# STM32F407 register map
File version: 1.2
CPU: CM4 r1p0, little endian, no MPU, no FPU, 4 interrupt priority bits
Registers are 32-bit, read-write, reset 0x0 unless marked. A register's access mark holds for its fields unless they carry their own. Offsets are from the block's base; [hi:lo] are bit positions.

## USART1 — Universal synchronous asynchronous receiver transmitter
Base 0x40011000
Same registers: USART2 0x40004400, USART3 0x40004800, USART6 0x40011400
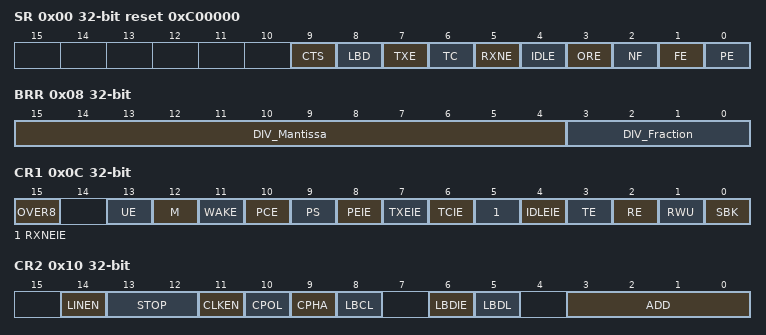
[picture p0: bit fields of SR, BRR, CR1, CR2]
0x00 SR access per field reset 0xC00000 — Status register
  [9] CTS rw — CTS flag
  [8] LBD rw — LIN break detection flag
  [7] TXE ro — Transmit data register empty
  [6] TC rw — Transmission complete
  [5] RXNE rw — Read data register not empty
  [4] IDLE ro — IDLE line detected
  [3] ORE ro — Overrun error
  [2] NF ro — Noise detected flag
  [1] FE ro — Framing error
  [0] PE ro — Parity error
0x04 DR — Data register
  [8:0] DR — Data value
0x08 BRR — Baud rate register
  [15:4] DIV_Mantissa — mantissa of USARTDIV
  [3:0] DIV_Fraction — fraction of USARTDIV
0x0C CR1 — Control register 1
  [15] OVER8 — Oversampling mode
    0=Oversample16 (Oversampling by 16); 1=Oversample8 (Oversampling by 8)
  [13] UE — USART enable
    0=Disabled (USART prescaler and outputs disabled); 1=Enabled (USART enabled)
  [12] M — Word length
    0=8 data bits; 1=9 data bits
  [11] WAKE — Wakeup method
    0=IdleLine (USART wakeup on idle line); 1=AddressMark (USART wakeup on address mark)
  [10] PCE — Parity control enable
    0=Disabled (Parity control disabled); 1=Enabled (Parity control enabled)
  [9] PS — Parity selection
    0=Even parity; 1=Odd (Odd parity)
  [8] PEIE — PE interrupt enable
    0=Disabled (PE interrupt disabled); 1=Enabled (PE interrupt enabled)
  [7] TXEIE — TXE interrupt enable
    0=Disabled (TXE interrupt disabled); 1=Enabled (TXE interrupt enabled)
  [6] TCIE — Transmission complete interrupt enable
    0=Disabled (TC interrupt disabled); 1=Enabled (TC interrupt enabled)
  [5] RXNEIE — RXNE interrupt enable
    0=Disabled (RXNE interrupt disabled); 1=Enabled (RXNE interrupt enabled)
  [4] IDLEIE — IDLE interrupt enable
    0=Disabled (IDLE interrupt disabled); 1=Enabled (IDLE interrupt enabled)
  [3] TE — Transmitter enable
    0=Disabled (Transmitter disabled); 1=Enabled (Transmitter enabled)
  [2] RE — Receiver enable
    0=Disabled (Receiver disabled); 1=Enabled (Receiver enabled)
  [1] RWU — Receiver wakeup
    0=Active (Receiver in active mode); 1=Mute (Receiver in mute mode)
  [0] SBK — Send break
    0=No break character is transmitted; 1=Break character transmitted
0x10 CR2 — Control register 2
  [14] LINEN — LIN mode enable
    0=Disabled (LIN mode disabled); 1=Enabled (LIN mode enabled)
  [13:12] STOP — STOP bits
    0=1 stop bit; 1=Stop0p5 (0.5 stop bits); 2=2 stop bits; 3=Stop1p5 (1.5 stop bits)
  [11] CLKEN — Clock enable
    0=Disabled (CK pin disabled); 1=Enabled (CK pin enabled)
  [10] CPOL — Clock polarity
    0=Low (Steady low value on CK pin outside transmission window); 1=High (Steady high value on CK pin outside transmission window)
  [9] CPHA — Clock phase
    0=First (The first clock transition is the first data capture edge); 1=Second (The second clock transition is the first data capture edge)
  [8] LBCL — Last bit clock pulse
  [6] LBDIE — LIN break detection interrupt enable
    0=Disabled (LIN break detection interrupt disabled); 1=Enabled (LIN break detection interrupt enabled)
  [5] LBDL — lin break detection length
    0=10-bit break detection; 1=11-bit break detection
  [3:0] ADD — Address of the USART node
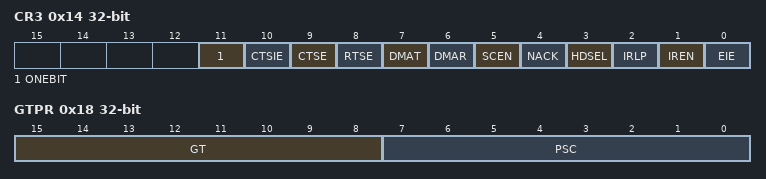
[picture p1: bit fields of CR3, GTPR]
0x14 CR3 — Control register 3
  [11] ONEBIT — One sample bit method enable
    0=Sample3 (Three sample bit method); 1=Sample1 (One sample bit method)
  [10] CTSIE — CTS interrupt enable
    0=Disabled (CTS interrupt disabled); 1=Enabled (CTS interrupt enabled)
  [9] CTSE — CTS enable
    0=Disabled (CTS hardware flow control disabled); 1=Enabled (CTS hardware flow control enabled)
  [8] RTSE — RTS enable
    0=Disabled (RTS hardware flow control disabled); 1=Enabled (RTS hardware flow control enabled)
  [7] DMAT — DMA enable transmitter
    0=Disabled (DMA mode is disabled for transmission); 1=Enabled (DMA mode is enabled for transmission)
  [6] DMAR — DMA enable receiver
    0=Disabled (DMA mode is disabled for reception); 1=Enabled (DMA mode is enabled for reception)
  [5] SCEN — Smartcard mode enable
    0=Disabled (Smartcard mode disabled); 1=Enabled (Smartcard mode enabled)
  [4] NACK — Smartcard NACK enable
    0=Disabled (NACK transmission in case of parity error is disabled); 1=Enabled (NACK transmission during parity error is enabled)
  [3] HDSEL — Half-duplex selection
    0=FullDuplex (Half duplex mode is not selected); 1=Half duplex mode is selected
  [2] IRLP — IrDA low-power
    0=Normal mode; 1=Low-power mode
  [1] IREN — IrDA mode enable
    0=Disabled (IrDA disabled); 1=Enabled (IrDA enabled)
  [0] EIE — Error interrupt enable
    0=Disabled (Error interrupt disabled); 1=Enabled (Error interrupt enabled)
0x18 GTPR — Guard time and prescaler register
  [15:8] GT — Guard time value
  [7:0] PSC — Prescaler value

## UART4 — Universal synchronous asynchronous receiver transmitter
Base 0x40004C00
Same registers: UART5 0x40005000, UART7 0x40007800, UART8 0x40007C00
Registers as USART1, without GTPR; these are added or differ:
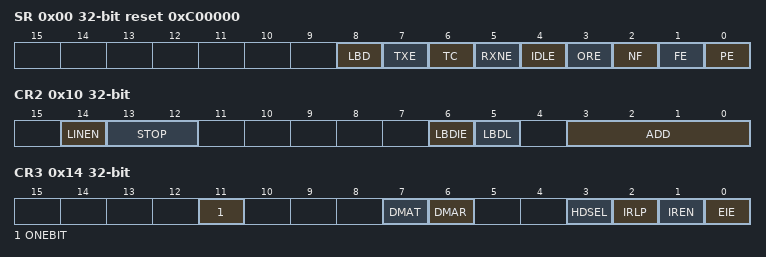
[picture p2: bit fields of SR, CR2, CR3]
0x00 SR access per field reset 0xC00000 — Status register
  [8] LBD rw — LIN break detection flag
  [7] TXE ro — Transmit data register empty
  [6] TC rw — Transmission complete
  [5] RXNE rw — Read data register not empty
  [4] IDLE ro — IDLE line detected
  [3] ORE ro — Overrun error
  [2] NF ro — Noise detected flag
  [1] FE ro — Framing error
  [0] PE ro — Parity error
0x10 CR2 — Control register 2
  [14] LINEN — LIN mode enable
    0=Disabled (LIN mode disabled); 1=Enabled (LIN mode enabled)
  [13:12] STOP — STOP bits
    0=1 stop bit; 2=2 stop bits
  [6] LBDIE — LIN break detection interrupt enable
    0=Disabled (LIN break detection interrupt disabled); 1=Enabled (LIN break detection interrupt enabled)
  [5] LBDL — lin break detection length
    0=10-bit break detection; 1=11-bit break detection
  [3:0] ADD — Address of the USART node
0x14 CR3 — Control register 3
  [11] ONEBIT — One sample bit method enable
    0=Sample3 (Three sample bit method); 1=Sample1 (One sample bit method)
  [7] DMAT — DMA enable transmitter
    0=Disabled (DMA mode is disabled for transmission); 1=Enabled (DMA mode is enabled for transmission)
  [6] DMAR — DMA enable receiver
    0=Disabled (DMA mode is disabled for reception); 1=Enabled (DMA mode is enabled for reception)
  [3] HDSEL — Half-duplex selection
    0=FullDuplex (Half duplex mode is not selected); 1=Half duplex mode is selected
  [2] IRLP — IrDA low-power
    0=Normal mode; 1=Low-power mode
  [1] IREN — IrDA mode enable
    0=Disabled (IrDA disabled); 1=Enabled (IrDA enabled)
  [0] EIE — Error interrupt enable
    0=Disabled (Error interrupt disabled); 1=Enabled (Error interrupt enabled)
